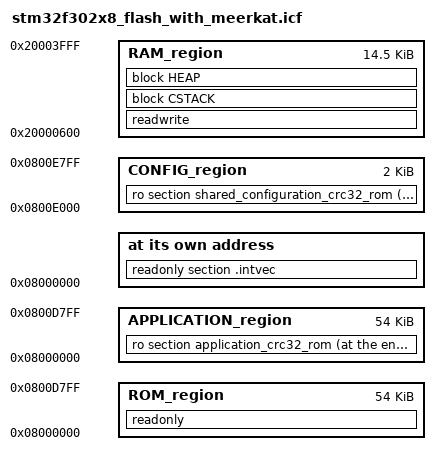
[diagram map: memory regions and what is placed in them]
/*###ICF### Section handled by ICF editor, don't touch! ****/
/*-Editor annotation file-*/
/* IcfEditorFile="$TOOLKIT_DIR$\config\ide\IcfEditor\cortex_v1_0.xml" */
/*-Specials-*/
define symbol __ICFEDIT_intvec_start__ = 0x08000000;
/*-Memory Regions-*/
// - Main Firmware ROM Space
define symbol __ICFEDIT_region_ROM_start__ = 0x08000000;
define symbol __ICFEDIT_region_ROM_end__   = 0x0800D7FF;
// - Saved Settings ROM Space
define symbol __ICFEDIT_region_SETTING_COPY_start__ = 0x0800D800;     /**reserve 4Kbyte for setting storage **/
define symbol __ICFEDIT_region_SETTING_COPY_end__   = 0x0800DFFF;
define symbol __ICFEDIT_region_SETTING_start__      = 0x0800E000;     /**reserve 4Kbyte for setting storage **/
define symbol __ICFEDIT_region_SETTING_end__        = 0x0800E7FF;
// - Safety Core ROM Space
define symbol __ICFEDIT_region_SAFETY_start__ = 0x0800E800;     /**reserve 4Kbyte for setting storage **/
define symbol __ICFEDIT_region_SAFETY_end__   = 0x0800FFFF;
// define symbol __ICFEDIT_region_RAM_start__ = 0x20000000;
// define symbol __ICFEDIT_region_RAM_end__   = 0x20003FFF;

/*-Sizes-*/
define symbol __ICFEDIT_size_cstack__ = 0x400;
define symbol __ICFEDIT_size_heap__   = 0x1000;
/**** End of ICF editor section. ###ICF###*/

// RAM Regions
// - Safety Core
// -- Total RAM Region occupied by Meerkat Safety Core (not directly used by this firmware)
define symbol __ICFEDIT_region_SAFETY_RAM_start__ = 0x20000000;
define symbol __ICFEDIT_region_SAFETY_RAM_end__   = 0x200005FF;
// --- SHARED_RAM or 'General Use RAM' 
// ---- RAM Objects from the Safety Core Partition accessible to this firmware
define symbol __ICFEDIT_region_SHARED_RAM_start__ = 0x200004C0; 
define symbol __ICFEDIT_region_SHARED_RAM_end__   = 0x200005FF;
// - Main Firmware
// -- Total RAM Region occupied by this firmware project.
define symbol __ICFEDIT_region_RAM_start__ = 0x20000600;
define symbol __ICFEDIT_region_RAM_end__   = 0x20003FFF;


define memory mem with size = 4G;
define region ROM_region      = mem:[from __ICFEDIT_region_ROM_start__   to __ICFEDIT_region_ROM_end__];
//define region SYSTEM_region   = mem:[from 0x08001000 to 0x08001FFF];
define region RAM_region      = mem:[from __ICFEDIT_region_RAM_start__   to __ICFEDIT_region_RAM_end__];

define block CSTACK    with alignment = 8, size = __ICFEDIT_size_cstack__   { };
define block HEAP      with alignment = 8, size = __ICFEDIT_size_heap__     { };

initialize by copy { readwrite };
do not initialize  { section .noinit };

place at address mem:__ICFEDIT_intvec_start__ { readonly section .intvec };

place in ROM_region   { readonly };
/*place in SYSTEM_region { readonly object scheduler.o, 
                         readonly object sequential_memory.o, 
                         readonly object structured_memory.o, 
                         readonly object ram_buffer.o,
                         readonly object ring_buffer.o,
                         readonly object driver_usart2.o,
                         readonly object module_usart2.o
                         };*/

place in RAM_region   { readwrite,
                        block CSTACK, block HEAP };

// CRC Calculation Extensions
// - Shared Configuration Area
define region CONFIG_region      = mem:[from __ICFEDIT_region_SETTING_start__   to __ICFEDIT_region_SETTING_end__];
place at end of CONFIG_region { ro section shared_configuration_crc32_rom };
// - Application Configuration Area
define region APPLICATION_region      = mem:[from __ICFEDIT_region_ROM_start__   to __ICFEDIT_region_ROM_end__];
place at end of APPLICATION_region { ro section application_crc32_rom };

// - Define/ Export Addresses for use by Post-Build Scripts (to populate Checksum information)
// -- Safety Firmware ROM Space
define symbol LNK_ROM_START = __ICFEDIT_region_ROM_start__;
export symbol LNK_ROM_START;
define symbol LNK_ROM_END = __ICFEDIT_region_ROM_end__;
export symbol LNK_ROM_END;
// -- Shared Configuration ROM Space
define symbol LNK_CFG_ROM_START = __ICFEDIT_region_SETTING_start__;
export symbol LNK_CFG_ROM_START;
define symbol LNK_CFG_ROM_END = __ICFEDIT_region_SETTING_end__;
export symbol LNK_CFG_ROM_END;
// -- Application Firmware ROM Space (will be overwritten by Application Firmware)
define symbol LNK_APP_ROM_START = __ICFEDIT_region_ROM_start__;
export symbol LNK_APP_ROM_START;
define symbol LNK_APP_ROM_END = __ICFEDIT_region_ROM_end__;
export symbol LNK_APP_ROM_END;
define symbol LNK_APP_ROM_CRC = __ICFEDIT_region_ROM_end__-3; // -3 because is a four byte value, at which ROM_end points to the last of
export symbol LNK_APP_ROM_CRC;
